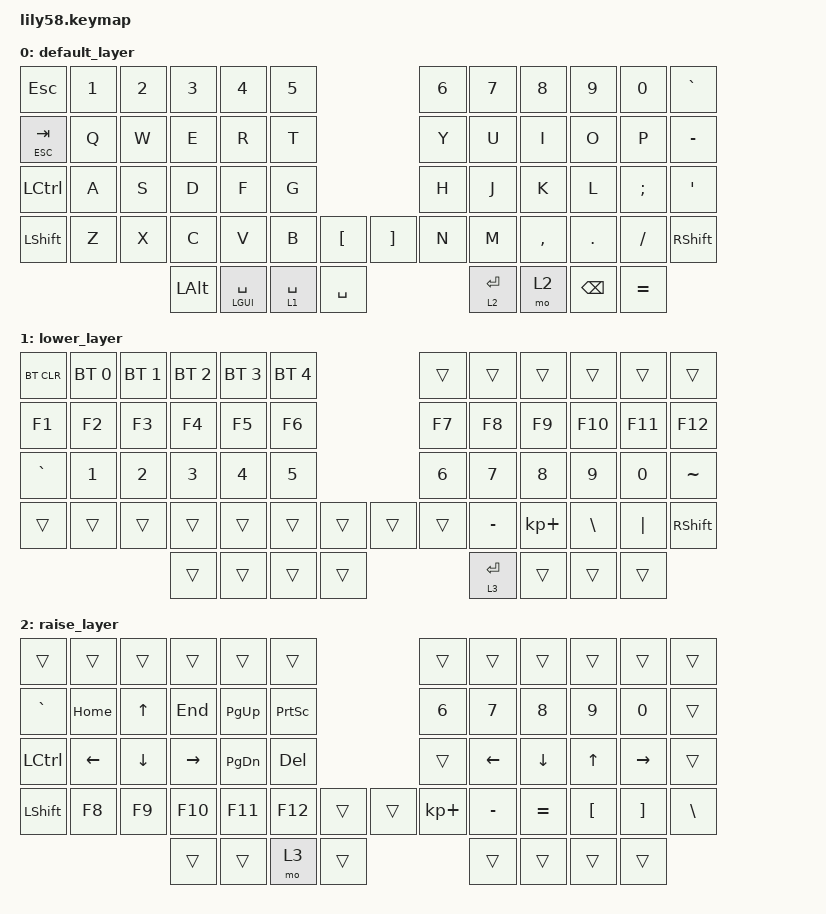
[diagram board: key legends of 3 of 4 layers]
/*
 * Copyright (c) 2020 The ZMK Contributors
 *
 * SPDX-License-Identifier: MIT
 */

#include <behaviors.dtsi>
#include <dt-bindings/zmk/keys.h>
#include <dt-bindings/zmk/bt.h>
#include <dt-bindings/zmk/ext_power.h>

/ {
	ext-power {
                init-delay-ms = <90>;
        };
	keymap {
		compatible = "zmk,keymap";

		default_layer {
// ------------------------------------------------------------------------------------------------------------
// |  ESC  |  1  |  2  |  3   |  4   |  5   |                   |  6   |  7    |  8    |  9   |   0   |   `   |
// |  TAB  |  Q  |  W  |  E   |  R   |  T   |                   |  Y   |  U    |  I    |  O   |   P   |   -   |
// |  CTRL |  A  |  S  |  D   |  F   |  G   |                   |  H   |  J    |  K    |  L   |   ;   |   '   |
// | SHIFT |  Z  |  X  |  C   |  V   |  B   |   "["  |  |  "]"  |  N   |  M    |  ,    |  .   |   /   | SHIFT |
//                     | ALT  | GUI  | ESC/L1 |  SPACE |  | ENTER/ R2 | RAISE| BSPC  | EQUAL   |
			bindings = <
&kp ESC   &kp N1 &kp N2 &kp N3   &kp N4   &kp N5                     &kp N6 &kp N7   &kp N8    &kp N9  &kp N0   &kp GRAVE
&lt ESC TAB  &kp Q  &kp W  &kp E    &kp R    &kp T                      &kp Y  &kp U    &kp I     &kp O   &kp P    &kp MINUS
&kp LCTRL &kp A  &kp S  &kp D    &kp F    &kp G                      &kp H  &kp J    &kp K     &kp L   &kp SEMI &kp SQT
&kp LSHFT &kp Z  &kp X  &kp C    &kp V    &kp B  &kp LBKT   &kp RBKT &kp N  &kp M    &kp COMMA &kp DOT &kp FSLH &kp RSHFT
                        &kp LALT &lt LGUI SPACE &lt 1 SPACE  &kp SPACE  &lt 2 RET  &mo 2  &kp BSPC &kp EQUAL
			>;

			sensor-bindings = <&inc_dec_kp C_VOL_UP C_VOL_DN>;
		};

		lower_layer {
// ------------------------------------------------------------------------------------------------------------
// | BTCLR | BT1 | BT2 |  BT3 |  BT4 |  BT5 |                   |      |       |       |      |       |       |
// |  F1   |  F2 |  F3 |  F4  |  F5  |  F6  |                   |  F7  |  F8   |  F9   |  F10 |  F11  |  F12  |
// |   `   |  1  |  2  |  3   |  4   |  5   |                   |  6   |  7    |  8    |  9   |   0   |   ~      |
// |       |     |     |      |      |      |        |  |       |      |  _    |  +    |  BSLH  |   PIPE   |  RSHIFT  |
//                     |      |      |      |        |  |       |      |       |       |
			bindings = <
&bt BT_CLR &bt BT_SEL 0     &bt BT_SEL 1      &bt BT_SEL 2      &bt BT_SEL 3 &bt BT_SEL 4                        &trans    &trans    &trans          &trans    &trans    &trans
&kp F1     &kp F2           &kp F3            &kp F4            &kp F5       &kp F6                              &kp F7    &kp F8    &kp F9          &kp F10   &kp F11   &kp F12
&kp GRAVE  &kp N1           &kp N2            &kp N3            &kp N4       &kp N5                              &kp N6   &kp N7    &kp N8    &kp N9          &kp N0    &kp TILDE
&trans     &trans          &trans             &trans            &trans       &trans    &trans          &trans    &trans    &kp MINUS &kp KP_PLUS     &kp BSLH  &kp PIPE  &kp RSHFT
                                              &trans            &trans       &trans    &trans                    &lt 3 RET    &trans    &trans    &trans
			>;

			sensor-bindings = <&inc_dec_kp C_VOL_UP C_VOL_DN>;
		};

		raise_layer {
// ------------------------------------------------------------------------------------------------------------
// |       |      |     |      |      |      |                   |      |       |       |      |       |       |
// |   `   | HOME | UP  |  END |PG_UP |  PSCRN   |                   |  6   |   7   |   8   |  9   |   0   |       |
// | LCTRL | LEFT |DOWN |RIGHT |PG_DN |  DEL  |                   |      |   <-  |   v   |  ^   |  ->   |       |
// | LSHFT |  F8  |  F9 |  F10 |  F11 |  F12 |        |  |       |  +   |   -   |   =   |  [   |   ]   |   \   |
//                     |       |       |      |        |  |       |      |       |       |
			bindings = <
&trans    &trans   &trans   &trans    &trans  &trans                       &trans      &trans    &trans    &trans   &trans    &trans
&kp GRAVE &kp HOME &kp UP   &kp END   &kp PG_UP  &kp PSCRN                 &kp N6      &kp N7    &kp N8    &kp N9   &kp N0    &trans
&kp LCTRL &kp LEFT &kp DOWN &kp RIGHT &kp PG_DN  &kp DEL                   &trans      &kp LEFT  &kp DOWN  &kp UP   &kp RIGHT &trans
&kp LSHFT &kp F8   &kp F9   &kp F10   &kp F11 &kp F12   &trans   &trans    &kp KP_PLUS &kp MINUS &kp EQUAL &kp LBKT &kp RBKT  &kp BSLH
                        &trans  &trans  &mo 3    &trans   &trans    &trans      &trans    &trans
			>;

			sensor-bindings = <&inc_dec_kp C_VOL_UP C_VOL_DN>;
		};


				adjust_layer {
// ------------------------------------------------------------------------------------------------------------
// |       |      |     |      |      |      |                   |      |       |       |      |       |       |
// |   `   | HOME | UP  |  END |PG_UP |  PSCRN   |                   |  6   |   7   |   8   |  9   |   0   |       |
// | LCTRL | LEFT |DOWN |RIGHT |PG_DN |  DEL  |                   |      |   <-  |   v   |  ^   |  ->   |       |
// | LSHFT |  F8  |  F9 |  F10 |  F11 |  F12 |        |  |       |  +   |   -   |   =   |  [   |   ]   |   \   |
//                     |       |       |      |        |  |       |      |       |       |
			bindings = <
&bt BT_CLR    &bt BT_NXT   &bt BT_PRV   &trans    &trans  &trans                       &bt BT_SEL 0      &bt BT_SEL 1    &bt BT_SEL 2    &bt BT_SEL 3   &bt BT_SEL 4    &none
&trans    &ext_power EP_ON &ext_power EP_OFF &ext_power EP_TOG    &kp END   &kp PG_UP  &kp PSCRN                 &kp N6      &kp N7    &kp N8    &kp N9   &kp N0    &trans
&kp LCTRL &kp LEFT &kp DOWN &kp RIGHT &kp PG_DN  &kp DEL                   &trans      &kp LEFT  &kp DOWN  &kp UP   &kp RIGHT &trans
&kp LSHFT &kp F8   &kp F9   &kp F10   &kp F11 &kp F12   &trans   &trans    &kp KP_PLUS &kp MINUS &kp EQUAL &kp LBKT &kp RBKT  &kp BSLH
                        &trans  &trans  &mo 3    &trans   &trans    &trans      &trans    &trans
			>;

			sensor-bindings = <&inc_dec_kp C_VOL_UP C_VOL_DN>;
		};

	// 	adjust_layer {
     
	 
	 
	//  bindings = <
    //     &kp BT_CLR  &kp BT_NXT  &kp BT_PRV  &none  &none  &none              &kp BT_SEL 0    &kp BT_SEL 1       &kp BT_SEL 2        &kp BT_SEL 3        &kp BT_SEL 4   &kp BT_SEL 5
    //     &kp F1 &kp F2 &kp F3 &kp F4 &kp F5 &kp F6                   &kp F7       &kp F8       &kp F9       &kp F10      &kp F11 &kp F12
    //     &trans &none  &none  &none  &none  &none                    &no &none &none &none &none   &none
    //     &trans &none  &none  &none  &none  &none  &none      &none  &none        &none        &none        &none        &none   &trans
    //                          &none  &trans &trans &trans     &trans &trans       &trans       &none
    //   >;

	//   sensor-bindings = <&inc_dec_kp C_VOL_UP C_VOL_DN>;
    // };
	};
};
